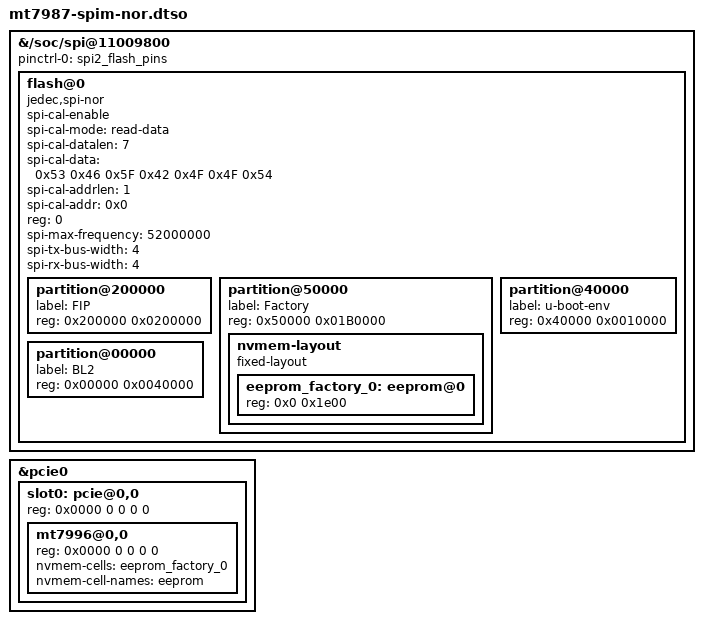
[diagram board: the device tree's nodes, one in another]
// SPDX-License-Identifier: (GPL-2.0 OR MIT)

/dts-v1/;
/plugin/;

/ {
	fragment@0 {
		target-path = "/soc/spi@11009800";
		__overlay__ {
			pinctrl-names = "default";
			pinctrl-0 = <&spi2_flash_pins>;
			status = "okay";

			flash@0 {
				#address-cells = <1>;
				#size-cells = <1>;
				compatible = "jedec,spi-nor";
				spi-cal-enable;
				spi-cal-mode = "read-data";
				spi-cal-datalen = <7>;
				spi-cal-data = /bits/ 8 <
					0x53 0x46 0x5F 0x42 0x4F 0x4F 0x54>;
				spi-cal-addrlen = <1>;
				spi-cal-addr = /bits/ 32 <0x0>;
				reg = <0>;
				spi-max-frequency = <52000000>;
				spi-tx-bus-width = <4>;
				spi-rx-bus-width = <4>;

				partition@200000 {
					label = "FIP";
					reg = <0x200000 0x0200000>;
				};
				partition@50000 {
					label = "Factory";
					reg = <0x50000 0x01B0000>;

					nvmem-layout {
						compatible = "fixed-layout";
						#address-cells = <1>;
						#size-cells = <1>;

						eeprom_factory_0: eeprom@0 {
							reg = <0x0 0x1e00>;
						};
					};
				};
				partition@40000 {
					label = "u-boot-env";
					reg = <0x40000 0x0010000>;
				};
				partition@00000 {
					label = "BL2";
					reg = <0x00000 0x0040000>;
				};
			};
		};
	};

	fragment@1 {
		target = <&pcie0>;
		__overlay__ {
			slot0: pcie@0,0 {
				reg = <0x0000 0 0 0 0>;
				mt7996@0,0 {
					reg = <0x0000 0 0 0 0>;
					nvmem-cells = <&eeprom_factory_0>;
					nvmem-cell-names = "eeprom";
				};
			};
		};
	};
};

